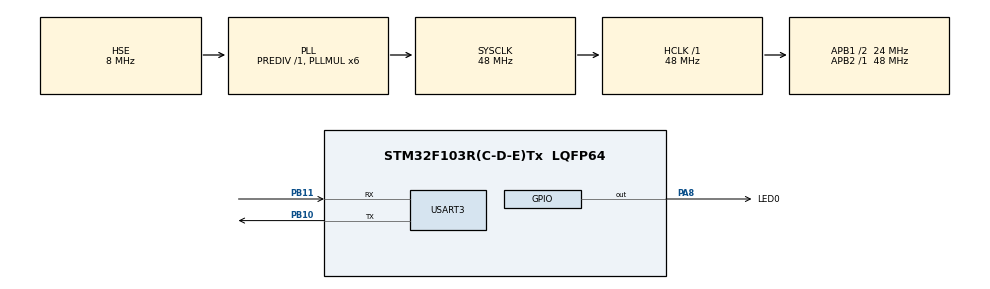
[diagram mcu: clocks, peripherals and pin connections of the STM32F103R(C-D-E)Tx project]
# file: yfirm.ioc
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Mcu.Family=STM32F1
Mcu.Name=STM32F103R(C-D-E)Tx
Mcu.Package=LQFP64
NVIC.PriorityGroup=NVIC_PRIORITYGROUP_4
PA13.Mode=Serial_Wire
PA13.Signal=SYS_JTMS-SWDIO
PA14.Mode=Serial_Wire
PA14.Signal=SYS_JTCK-SWCLK
PA8.GPIO_Label=LED0
PA8.Signal=GPIO_Output
PB10.Mode=Asynchronous
PB10.Signal=USART3_TX
PB11.Mode=Asynchronous
PB11.Signal=USART3_RX
PC14-OSC32_IN.Mode=LSE-External-Oscillator
PC14-OSC32_IN.Signal=RCC_OSC32_IN
PC15-OSC32_OUT.Mode=LSE-External-Oscillator
PC15-OSC32_OUT.Signal=RCC_OSC32_OUT
PD0-OSC_IN.Mode=HSE-External-Oscillator
PD0-OSC_IN.Signal=RCC_OSC_IN
PD1-OSC_OUT.Mode=HSE-External-Oscillator
PD1-OSC_OUT.Signal=RCC_OSC_OUT
ProjectManager.HeapSize=0x200
ProjectManager.StackSize=0x400
ProjectManager.TargetToolchain=STM32CubeIDE
RCC.AHBFreq_Value=48000000
RCC.APB1CLKDivider=RCC_HCLK_DIV2
RCC.APB1Freq_Value=24000000
RCC.APB1TimFreq_Value=48000000
RCC.APB2Freq_Value=48000000
RCC.APB2TimFreq_Value=48000000
RCC.HCLKFreq_Value=48000000
RCC.PLLMUL=RCC_PLL_MUL6
RCC.PLLSourceVirtual=RCC_PLLSOURCE_HSE
RCC.RTCClockSelection=RCC_RTCCLKSOURCE_LSE
RCC.SYSCLKFreq_VALUE=48000000
RCC.SYSCLKSource=RCC_SYSCLKSOURCE_PLLCLK
RCC.USBFreq_Value=48000000
USART3.VirtualMode=VM_ASYNC
VP_RTC_VS_RTC_Activate.Mode=RTC_Enabled
VP_RTC_VS_RTC_Calendar.Mode=RTC_Calendar
board=custom

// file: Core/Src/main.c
/* USER CODE BEGIN Header */
/**
  ******************************************************************************
  * @file           : main.c
  * @brief          : Main program body
  ******************************************************************************
  * @attention
  *
  * Copyright (c) 2022 STMicroelectronics.
  * All rights reserved.
  *
  * This software is licensed under terms that can be found in the LICENSE file
  * in the root directory of this software component.
  * If no LICENSE file comes with this software, it is provided AS-IS.
  *
  ******************************************************************************
  */
#include <stdio.h>

/* USER CODE END Header */
#include "main.h"
#include "rtc.h"
#include "usart.h"
#include "gpio.h"

/* USER CODE BEGIN PTD */
uint32_t counter=0;
/* USER CODE END PTD */

void SystemClock_Config(void);

/* USER CODE BEGIN 0 */
#ifdef __GNUC__
/* With GCC, small printf (option LD Linker->Libraries->Small printf
 set to 'Yes') calls __io_putchar() */
#define PUTCHAR_PROTOTYPE int __io_putchar(int ch)
#else
#define PUTCHAR_PROTOTYPE int fputc(int ch, FILE *f)
#endif /* __GNUC__ */
/* USER CODE END 0 */

int main(void)
{

  /* MCU Configuration--------------------------------------------------------*/

  /* Reset of all peripherals, Initializes the Flash interface and the Systick. */
  HAL_Init();

  /* Configure the system clock */
  SystemClock_Config();

  /* Initialize all configured peripherals */
  MX_GPIO_Init();
  MX_RTC_Init();
  MX_USART3_UART_Init();
  /* USER CODE BEGIN 2 */
  printf("hello firmware\r\n");
  /* USER CODE END 2 */

  /* Infinite loop */
  while (1)
  {

    /* USER CODE BEGIN 3 */
	  HAL_Delay(100);
	  HAL_GPIO_TogglePin(LED0_GPIO_Port, LED0_Pin);
	  counter++;
	  if(counter > 20){
		  counter=0;
		  printf("firm\r\n");
	  }
  }
  /* USER CODE END 3 */
}

void SystemClock_Config(void)
{
  RCC_OscInitTypeDef RCC_OscInitStruct = {0};
  RCC_ClkInitTypeDef RCC_ClkInitStruct = {0};
  RCC_PeriphCLKInitTypeDef PeriphClkInit = {0};

  /** Initializes the RCC Oscillators according to the specified parameters
  * in the RCC_OscInitTypeDef structure.
  */
  RCC_OscInitStruct.OscillatorType = RCC_OSCILLATORTYPE_HSE|RCC_OSCILLATORTYPE_LSE;
  RCC_OscInitStruct.HSEState = RCC_HSE_ON;
  RCC_OscInitStruct.HSEPredivValue = RCC_HSE_PREDIV_DIV1;
  RCC_OscInitStruct.LSEState = RCC_LSE_ON;
  RCC_OscInitStruct.HSIState = RCC_HSI_ON;
  RCC_OscInitStruct.PLL.PLLState = RCC_PLL_ON;
  RCC_OscInitStruct.PLL.PLLSource = RCC_PLLSOURCE_HSE;
  RCC_OscInitStruct.PLL.PLLMUL = RCC_PLL_MUL6;
  if (HAL_RCC_OscConfig(&RCC_OscInitStruct) != HAL_OK)
  {
    Error_Handler();
  }

  /** Initializes the CPU, AHB and APB buses clocks
  */
  RCC_ClkInitStruct.ClockType = RCC_CLOCKTYPE_HCLK|RCC_CLOCKTYPE_SYSCLK
                              |RCC_CLOCKTYPE_PCLK1|RCC_CLOCKTYPE_PCLK2;
  RCC_ClkInitStruct.SYSCLKSource = RCC_SYSCLKSOURCE_PLLCLK;
  RCC_ClkInitStruct.AHBCLKDivider = RCC_SYSCLK_DIV1;
  RCC_ClkInitStruct.APB1CLKDivider = RCC_HCLK_DIV2;
  RCC_ClkInitStruct.APB2CLKDivider = RCC_HCLK_DIV1;

  if (HAL_RCC_ClockConfig(&RCC_ClkInitStruct, FLASH_LATENCY_1) != HAL_OK)
  {
    Error_Handler();
  }
  PeriphClkInit.PeriphClockSelection = RCC_PERIPHCLK_RTC;
  PeriphClkInit.RTCClockSelection = RCC_RTCCLKSOURCE_LSE;
  if (HAL_RCCEx_PeriphCLKConfig(&PeriphClkInit) != HAL_OK)
  {
    Error_Handler();
  }
}

/* USER CODE BEGIN 4 */
/**
 * @brief  Retargets the C library printf function to the USART.
 * @param  None
 * @retval None
 */
PUTCHAR_PROTOTYPE {
	/* Place your implementation of fputc here */
	/* e.g. write a character to the USART1 and Loop until the end of transmission */
	HAL_UART_Transmit(&huart3, (uint8_t*) &ch, 1, 0xFFFF);

	return ch;
}
/* USER CODE END 4 */

void Error_Handler(void)
{
  __disable_irq();
  while (1)
  {
  }
}
